AUTOSAR XML (schema 4-3-0)
package /SWC_Switch
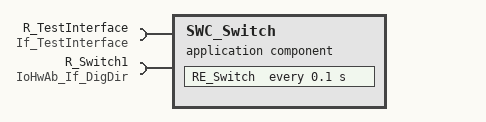
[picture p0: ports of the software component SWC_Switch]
  application sw component type SWC_Switch
    require port R_TestInterface: client-com-spec=TestOperation, required-interface=If_TestInterface
    require port R_Switch1: client-com-spec=ReadDirect, required-interface=IoHwAb_If_DigDir
    behavior InternalBehavior
      timing event TE_RE_Switch: start-on-event=RE_Switch, period=0.1
      runnable RE_Switch
        sync call SSCP_RE_Switch_R_Switch1_ReadDirect: operation=R_Switch1.ReadDirect
        sync call SSCP_RE_Switch_R_TestInterface_TestOperation: operation=R_TestInterface.TestOperation
